# HDSC_HC32M423 register map
Vendor: HDSC Co.,Ltd.; Series: ARMCM4; File version: 1.0
CPU: CM4 r0p1, little endian, MPU, FPU, 4 interrupt priority bits
Registers are 32-bit, read-write, reset 0x0 unless marked. A register's access mark holds for its fields unless they carry their own. Offsets are from the block's base; [hi:lo] are bit positions; {n}, {i} and the like mark numbered series.

## CRC
Base 0x40050400
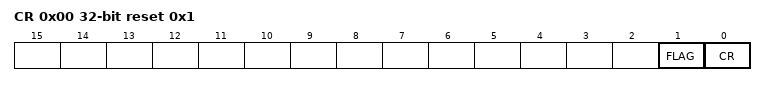
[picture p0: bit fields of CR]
0x00 CR reset 0x1
  [1] FLAG, [0] CR
0x04 RESLT
{0x80+4i} DAT{i} (i=0..31)

## CTC
Base 0x40010000
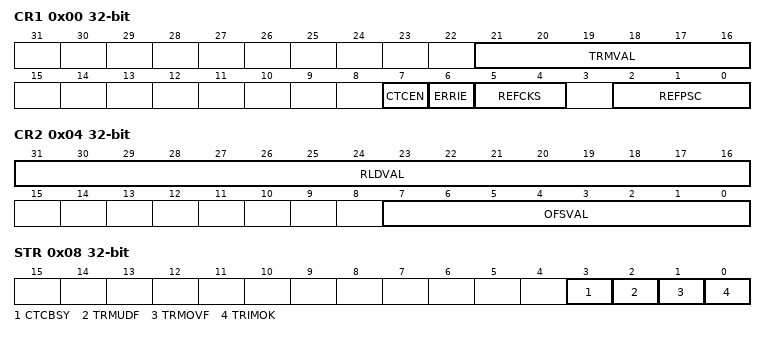
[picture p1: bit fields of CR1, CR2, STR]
0x00 CR1
  [21:16] TRMVAL, [7] CTCEN, [6] ERRIE, [5:4] REFCKS, [2:0] REFPSC
0x04 CR2
  [31:16] RLDVAL, [7:0] OFSVAL
0x08 STR ro
  [3] CTCBSY, [2] TRMUDF, [1] TRMOVF, [0] TRIMOK

## DAC
Base 0x4004A100
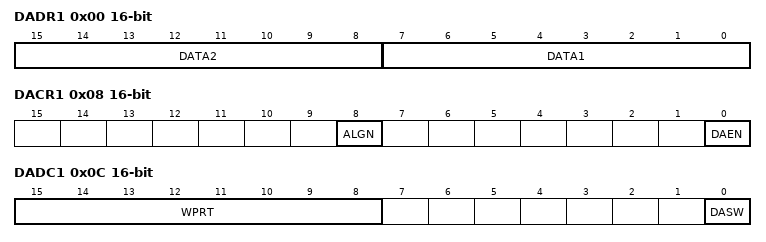
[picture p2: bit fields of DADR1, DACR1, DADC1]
0x00 DADR1 16-bit
  [15:8] DATA2, [7:0] DATA1
0x08 DACR1 16-bit
  [8] ALGN, [0] DAEN
0x0C DADC1 16-bit
  [15:8] WPRT, [0] DASW

## DBGC
Base 0xE0042000
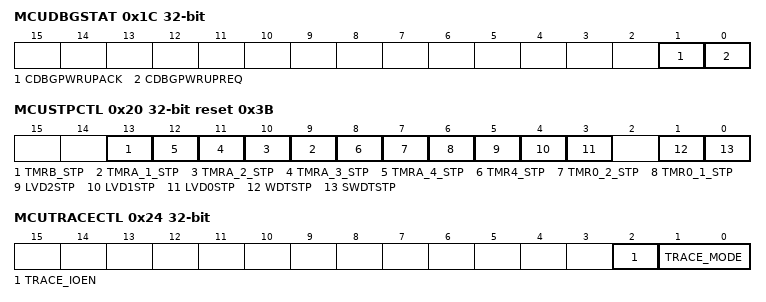
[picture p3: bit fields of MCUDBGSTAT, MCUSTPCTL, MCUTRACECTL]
0x1C MCUDBGSTAT
  [1] CDBGPWRUPACK, [0] CDBGPWRUPREQ
0x20 MCUSTPCTL reset 0x3B
  [13] TMRB_STP, [n+8] TMRA_{n}_STP (n=1..4), [8] TMR4_STP, [7] TMR0_2_STP, [6] TMR0_1_STP, [5] LVD2STP, [4] LVD1STP, [3] LVD0STP, [1] WDTSTP, [0] SWDTSTP
0x24 MCUTRACECTL
  [2] TRACE_IOEN, [1:0] TRACE_MODE

## DCU
Base 0x40052000
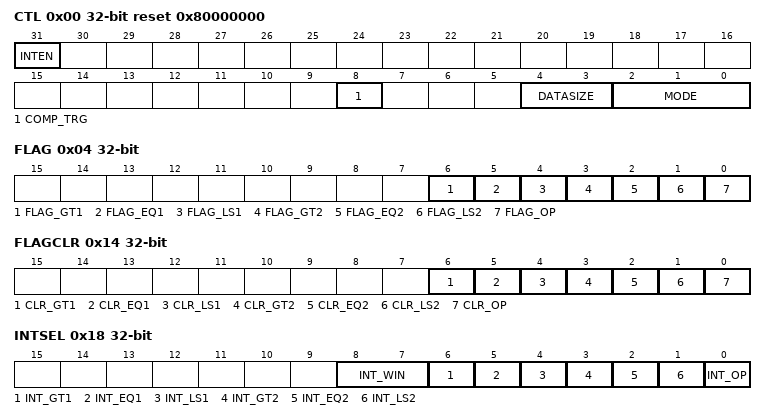
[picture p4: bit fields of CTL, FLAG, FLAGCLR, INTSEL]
0x00 CTL reset 0x80000000
  [31] INTEN, [8] COMP_TRG, [4:3] DATASIZE, [2:0] MODE
0x04 FLAG ro
  [6] FLAG_GT1, [5] FLAG_EQ1, [4] FLAG_LS1, [3] FLAG_GT2, [2] FLAG_EQ2, [1] FLAG_LS2, [0] FLAG_OP
{0x8+4i} DATA{i} (i=0..2)
0x14 FLAGCLR wo
  [6] CLR_GT1, [5] CLR_EQ1, [4] CLR_LS1, [3] CLR_GT2, [2] CLR_EQ2, [1] CLR_LS2, [0] CLR_OP
0x18 INTSEL
  [8:7] INT_WIN, [6] INT_GT1, [5] INT_EQ1, [4] INT_LS1, [3] INT_GT2, [2] INT_EQ2, [1] INT_LS2, [0] INT_OP

## DMA
Base 0x40053000
0x00 EN
  [0] EN
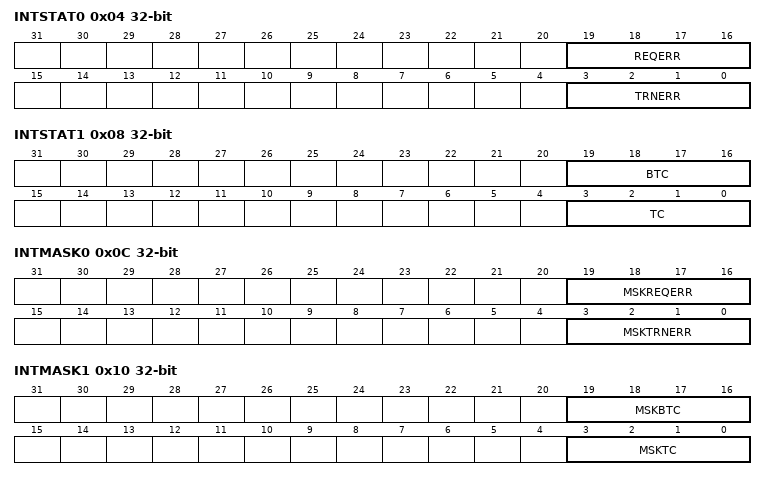
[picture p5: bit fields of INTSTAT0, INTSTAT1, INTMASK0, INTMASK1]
0x04 INTSTAT0 ro
  [19:16] REQERR, [3:0] TRNERR
0x08 INTSTAT1 ro
  [19:16] BTC, [3:0] TC
0x0C INTMASK0
  [19:16] MSKREQERR, [3:0] MSKTRNERR
0x10 INTMASK1
  [19:16] MSKBTC, [3:0] MSKTC
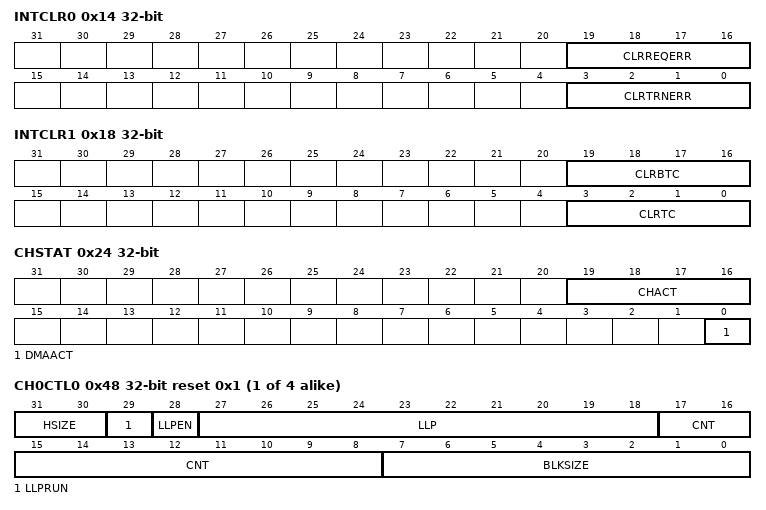
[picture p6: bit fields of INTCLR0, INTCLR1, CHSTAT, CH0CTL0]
0x14 INTCLR0 wo
  [19:16] CLRREQERR, [3:0] CLRTRNERR
0x18 INTCLR1 wo
  [19:16] CLRBTC, [3:0] CLRTC
0x1C CHEN
  [3:0] CHEN
0x24 CHSTAT ro
  [19:16] CHACT, [0] DMAACT
0x30 RAM_LLP reset 0x20000000
  [31:14] LLP
0x34 ROM_LLP
  [31:14] LLP
0x38 CHENCLR wo
  [3:0] CHENCLR
{0x40+0x40*i} SAR{i} (i=0..3)
{0x44+0x40*i} DAR{i} (i=0..3)
{0x48+0x40*i} CH{i}CTL0 reset 0x1 (i=0..3)
  [31:30] HSIZE, [29] LLPRUN, [28] LLPEN, [27:18] LLP, [17:8] CNT, [7:0] BLKSIZE
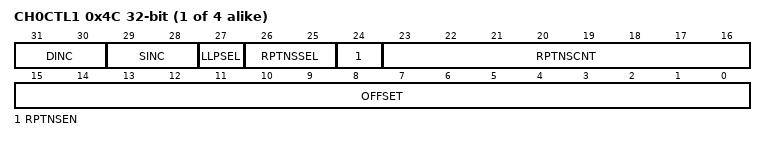
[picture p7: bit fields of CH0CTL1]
{0x4C+0x40*i} CH{i}CTL1 (i=0..3)
  [31:30] DINC, [29:28] SINC, [27] LLPSEL, [26:25] RPTNSSEL, [24] RPTNSEN, [23:16] RPTNSCNT, [15:0] OFFSET

## EFM
Base 0x40010400
0x00 FAPRT
  [15:0] FAPRT
0x04 FSTP
  [0] FSTP
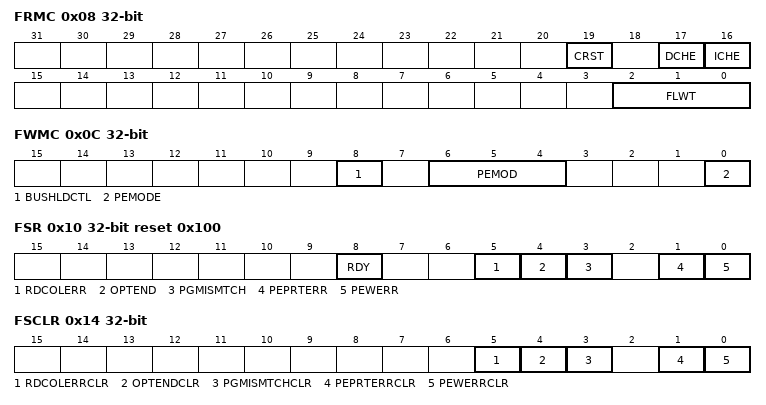
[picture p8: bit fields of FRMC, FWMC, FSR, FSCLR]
0x08 FRMC
  [19] CRST, [17] DCHE, [16] ICHE, [2:0] FLWT
0x0C FWMC
  [8] BUSHLDCTL, [6:4] PEMOD, [0] PEMODE
0x10 FSR ro reset 0x100
  [8] RDY, [5] RDCOLERR, [4] OPTEND, [3] PGMISMTCH, [1] PEPRTERR, [0] PEWERR
0x14 FSCLR
  [5] RDCOLERRCLR, [4] OPTENDCLR, [3] PGMISMTCHCLR, [1] PEPRTERRCLR, [0] PEWERRCLR
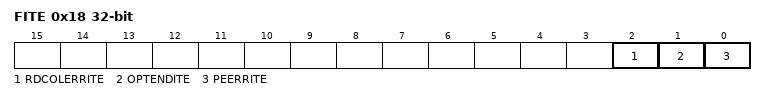
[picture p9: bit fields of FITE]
0x18 FITE
  [2] RDCOLERRITE, [1] OPTENDITE, [0] PEERRITE
0x20 FPMTSW
  [16:0] FPMTSW
0x24 FPMTEW
  [16:0] FPMTEW
{0x50+4i} UQID{i} ro (i=0..3)
0x282 HRCCFGR 8-bit
  [3:0] HRCFREQS

## EMBG0
Base 0x40017C00
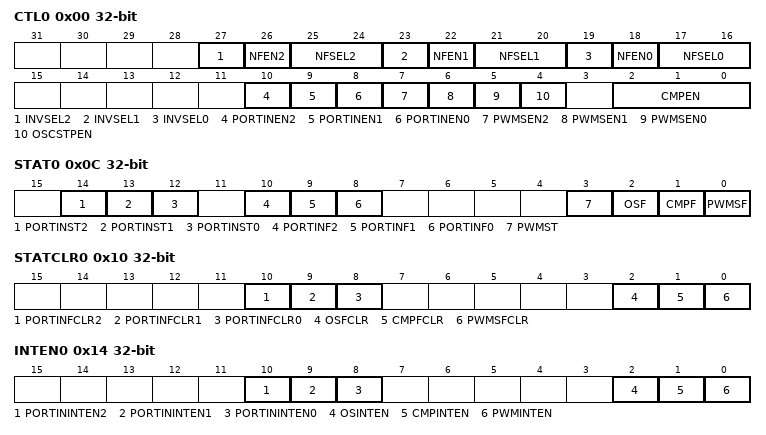
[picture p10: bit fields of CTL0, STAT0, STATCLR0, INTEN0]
0x00 CTL0
  [27] INVSEL2, [26] NFEN2, [25:24] NFSEL2, [23] INVSEL1, [22] NFEN1, [21:20] NFSEL1, [19] INVSEL0, [18] NFEN0, [17:16] NFSEL0, [10] PORTINEN2, [9] PORTINEN1, [8] PORTINEN0, [7] PWMSEN2, [6] PWMSEN1, [5] PWMSEN0, [4] OSCSTPEN, [2:0] CMPEN
0x04 PWMLV0
  [2:0] PWMLV
0x08 SOE0
  [0] SOE
0x0C STAT0 ro
  [14] PORTINST2 rw, [13] PORTINST1 rw, [12] PORTINST0 rw, [10] PORTINF2, [9] PORTINF1, [8] PORTINF0, [3] PWMST, [2] OSF, [1] CMPF, [0] PWMSF
0x10 STATCLR0 wo
  [10] PORTINFCLR2, [9] PORTINFCLR1, [8] PORTINFCLR0, [2] OSFCLR, [1] CMPFCLR, [0] PWMSFCLR
0x14 INTEN0
  [10] PORTININTEN2, [9] PORTININTEN1, [8] PORTININTEN0, [2] OSINTEN, [1] CMPINTEN, [0] PWMINTEN

## EMBG1
Base 0x40017C20
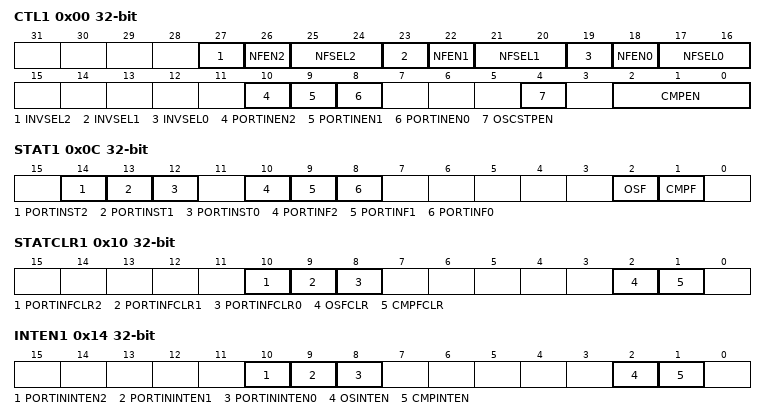
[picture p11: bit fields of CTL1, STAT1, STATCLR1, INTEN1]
0x00 CTL1
  [27] INVSEL2, [26] NFEN2, [25:24] NFSEL2, [23] INVSEL1, [22] NFEN1, [21:20] NFSEL1, [19] INVSEL0, [18] NFEN0, [17:16] NFSEL0, [10] PORTINEN2, [9] PORTINEN1, [8] PORTINEN0, [4] OSCSTPEN, [2:0] CMPEN
0x08 SOE1
  [0] SOE
0x0C STAT1 ro
  [14] PORTINST2 rw, [13] PORTINST1 rw, [12] PORTINST0 rw, [10] PORTINF2, [9] PORTINF1, [8] PORTINF0, [2] OSF, [1] CMPF
0x10 STATCLR1 wo
  [10] PORTINFCLR2, [9] PORTINFCLR1, [8] PORTINFCLR0, [2] OSFCLR, [1] CMPFCLR
0x14 INTEN1
  [10] PORTININTEN2, [9] PORTININTEN1, [8] PORTININTEN0, [2] OSINTEN, [1] CMPINTEN
0x18 ECSR
  [1:0] EMBVAL
